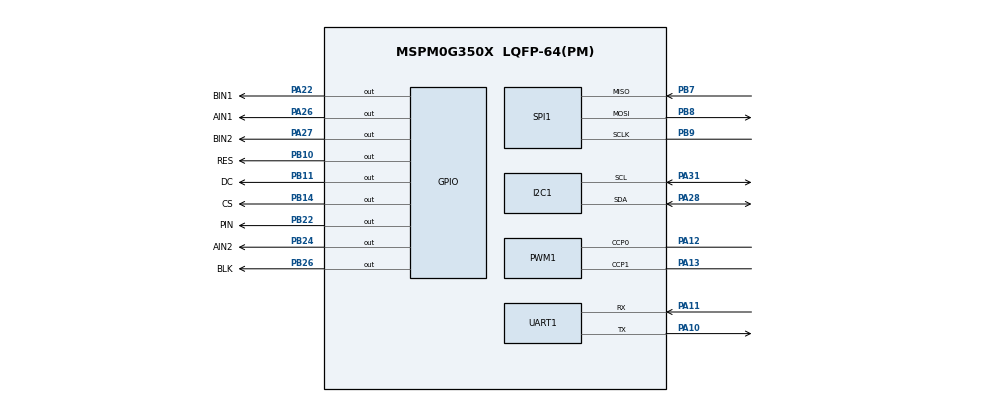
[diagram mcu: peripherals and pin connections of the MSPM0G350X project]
/**
 * @cliArgs --device "MSPM0G350X" --part "Default" --package "LQFP-64(PM)" --product "mspm0_sdk@2.04.00.06"
 * @versions {"tool":"1.23.0+4000"}
 */

/**
 * Import the modules used in this configuration.
 */
const GPIO   = scripting.addModule("/ti/driverlib/GPIO", {}, false);
const GPIO1  = GPIO.addInstance();
const GPIO2  = GPIO.addInstance();
const GPIO3  = GPIO.addInstance();
const I2C    = scripting.addModule("/ti/driverlib/I2C", {}, false);
const I2C1   = I2C.addInstance();
const PWM    = scripting.addModule("/ti/driverlib/PWM", {}, false);
const PWM1   = PWM.addInstance();
const SPI    = scripting.addModule("/ti/driverlib/SPI", {}, false);
const SPI1   = SPI.addInstance();
const SYSCTL = scripting.addModule("/ti/driverlib/SYSCTL");
const UART   = scripting.addModule("/ti/driverlib/UART", {}, false);
const UART1  = UART.addInstance();

/**
 * Write custom configuration values to the imported modules.
 */
const divider9       = system.clockTree["UDIV"];
divider9.divideValue = 2;

const mux4       = system.clockTree["EXHFMUX"];
mux4.inputSelect = "EXHFMUX_XTAL";

const mux8       = system.clockTree["HSCLKMUX"];
mux8.inputSelect = "HSCLKMUX_SYSPLL2X";

const mux12       = system.clockTree["SYSPLLMUX"];
mux12.inputSelect = "zSYSPLLMUX_HFCLK";

const pinFunction4        = system.clockTree["HFXT"];
pinFunction4.inputFreq    = 40;
pinFunction4.enable       = true;
pinFunction4.HFCLKMonitor = true;
pinFunction4.HFXTStartup  = 20;

GPIO1.$name                          = "LED";
GPIO1.associatedPins[0].$name        = "PIN";
GPIO1.associatedPins[0].ioStructure  = "SD";
GPIO1.associatedPins[0].assignedPort = "PORTB";
GPIO1.associatedPins[0].assignedPin  = "22";
GPIO1.associatedPins[0].pin.$assign  = "PB22";

const Board = scripting.addModule("/ti/driverlib/Board", {}, false);

GPIO2.$name                         = "LCD";
GPIO2.port                          = "PORTB";
GPIO2.associatedPins.create(4);
GPIO2.associatedPins[0].$name       = "RES";
GPIO2.associatedPins[0].assignedPin = "10";
GPIO2.associatedPins[0].ioStructure = "SD";
GPIO2.associatedPins[0].pin.$assign = "PB10";
GPIO2.associatedPins[1].$name       = "DC";
GPIO2.associatedPins[1].ioStructure = "SD";
GPIO2.associatedPins[1].assignedPin = "11";
GPIO2.associatedPins[1].pin.$assign = "PB11";
GPIO2.associatedPins[2].$name       = "CS";
GPIO2.associatedPins[2].assignedPin = "14";
GPIO2.associatedPins[2].ioStructure = "SD";
GPIO2.associatedPins[2].pin.$assign = "PB14";
GPIO2.associatedPins[3].$name       = "BLK";
GPIO2.associatedPins[3].assignedPin = "26";
GPIO2.associatedPins[3].ioStructure = "SD";
GPIO2.associatedPins[3].pin.$assign = "PB26";

GPIO3.$name                          = "GPIO_MOTOR";
GPIO3.associatedPins.create(4);
GPIO3.associatedPins[0].$name        = "AIN1";
GPIO3.associatedPins[0].pin.$assign  = "PA26";
GPIO3.associatedPins[1].$name        = "AIN2";
GPIO3.associatedPins[1].initialValue = "SET";
GPIO3.associatedPins[1].pin.$assign  = "PB24";
GPIO3.associatedPins[2].$name        = "BIN1";
GPIO3.associatedPins[2].pin.$assign  = "PA22";
GPIO3.associatedPins[3].$name        = "BIN2";
GPIO3.associatedPins[3].initialValue = "SET";
GPIO3.associatedPins[3].pin.$assign  = "PA27";

I2C1.basicEnableController             = true;
I2C1.basicControllerStandardBusSpeed   = "Fast";
I2C1.$name                             = "I2C_0";
I2C1.peripheral.$assign                = "I2C0";
I2C1.peripheral.sdaPin.$assign         = "PA28";
I2C1.peripheral.sclPin.$assign         = "PA31";
I2C1.sdaPinConfig.$name                = "ti_driverlib_gpio_GPIOPinGeneric7";
I2C1.sdaPinConfig.hideOutputInversion  = scripting.forceWrite(false);
I2C1.sdaPinConfig.onlyInternalResistor = scripting.forceWrite(false);
I2C1.sdaPinConfig.passedPeripheralType = scripting.forceWrite("Digital");
I2C1.sclPinConfig.$name                = "ti_driverlib_gpio_GPIOPinGeneric8";
I2C1.sclPinConfig.hideOutputInversion  = scripting.forceWrite(false);
I2C1.sclPinConfig.onlyInternalResistor = scripting.forceWrite(false);
I2C1.sclPinConfig.passedPeripheralType = scripting.forceWrite("Digital");

PWM1.$name                      = "PWM_0";
PWM1.timerStartTimer            = true;
PWM1.pwmMode                    = "EDGE_ALIGN_UP";
PWM1.peripheral.$assign         = "TIMG0";
PWM1.peripheral.ccp0Pin.$assign = "PA12";
PWM1.peripheral.ccp1Pin.$assign = "PA13";
PWM1.PWM_CHANNEL_0.$name        = "ti_driverlib_pwm_PWMTimerCC0";
PWM1.PWM_CHANNEL_0.dutyCycle    = 50;
PWM1.PWM_CHANNEL_1.$name        = "ti_driverlib_pwm_PWMTimerCC1";
PWM1.PWM_CHANNEL_1.dutyCycle    = 50;
PWM1.ccp0PinConfig.$name        = "ti_driverlib_gpio_GPIOPinGeneric5";
PWM1.ccp1PinConfig.$name        = "ti_driverlib_gpio_GPIOPinGeneric6";

SPI1.$name                              = "SPI_LCD";
SPI1.targetBitRate                      = 20000000;
SPI1.frameFormat                        = "MOTO3";
SPI1.sclkPinConfig.$name                = "ti_driverlib_gpio_GPIOPinGeneric2";
SPI1.sclkPinConfig.direction            = scripting.forceWrite("OUTPUT");
SPI1.sclkPinConfig.onlyInternalResistor = scripting.forceWrite(false);
SPI1.sclkPinConfig.passedPeripheralType = scripting.forceWrite("Digital");
SPI1.mosiPinConfig.$name                = "ti_driverlib_gpio_GPIOPinGeneric3";
SPI1.mosiPinConfig.direction            = scripting.forceWrite("OUTPUT");
SPI1.mosiPinConfig.hideOutputInversion  = scripting.forceWrite(false);
SPI1.mosiPinConfig.onlyInternalResistor = scripting.forceWrite(false);
SPI1.mosiPinConfig.passedPeripheralType = scripting.forceWrite("Digital");
SPI1.misoPinConfig.$name                = "ti_driverlib_gpio_GPIOPinGeneric4";
SPI1.misoPinConfig.onlyInternalResistor = scripting.forceWrite(false);
SPI1.misoPinConfig.passedPeripheralType = scripting.forceWrite("Digital");
SPI1.peripheral.$assign                 = "SPI1";
SPI1.peripheral.sclkPin.$assign         = "PB9";
SPI1.peripheral.mosiPin.$assign         = "PB8";
SPI1.peripheral.misoPin.$assign         = "PB7";

SYSCTL.forceDefaultClkConfig = true;
SYSCTL.clockTreeEn           = true;
SYSCTL.validateClkStatus     = true;

UART1.$name                        = "UART_0";
UART1.targetBaudRate               = 115200;
UART1.peripheral.$assign           = "UART0";
UART1.peripheral.rxPin.$assign     = "PA11";
UART1.peripheral.txPin.$assign     = "PA10";
UART1.txPinConfig.$name            = "ti_driverlib_gpio_GPIOPinGeneric0";
UART1.txPinConfig.enableConfig     = true;
UART1.txPinConfig.internalResistor = "PULL_UP";
UART1.rxPinConfig.$name            = "ti_driverlib_gpio_GPIOPinGeneric1";
UART1.rxPinConfig.enableConfig     = true;
UART1.rxPinConfig.internalResistor = "PULL_UP";

/**
 * Pinmux solution for unlocked pins/peripherals. This ensures that minor changes to the automatic solver in a future
 * version of the tool will not impact the pinmux you originally saw.  These lines can be completely deleted in order to
 * re-solve from scratch.
 */
pinFunction4.peripheral.$suggestSolution           = "SYSCTL";
pinFunction4.peripheral.hfxInPin.$suggestSolution  = "PA5";
pinFunction4.peripheral.hfxOutPin.$suggestSolution = "PA6";
Board.peripheral.$suggestSolution                  = "DEBUGSS";
Board.peripheral.swclkPin.$suggestSolution         = "PA20";
Board.peripheral.swdioPin.$suggestSolution         = "PA19";
